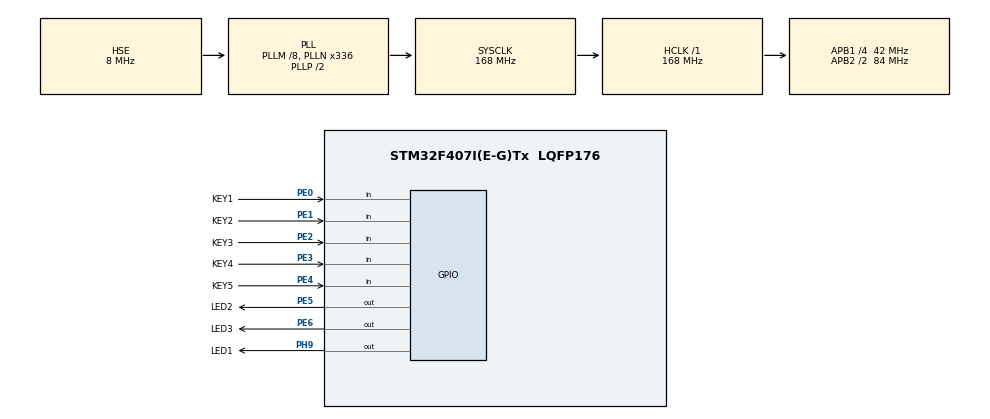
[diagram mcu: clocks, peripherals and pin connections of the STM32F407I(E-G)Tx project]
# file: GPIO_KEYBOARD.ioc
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Mcu.Family=STM32F4
PE0.GPIO_PuPd=GPIO_PULLUP
RCC.PLLSourceVirtual=RCC_PLLSOURCE_HSE
PH0-OSC_IN.Signal=RCC_OSC_IN
RCC.CortexFreq_Value=168000000
PE1.GPIO_PuPd=GPIO_PULLUP
PH9.GPIO_Speed=GPIO_SPEED_FREQ_VERY_HIGH
RCC.APB1CLKDivider=RCC_HCLK_DIV4
PE6.GPIO_Label=LED3
RCC.SYSCLKSource=RCC_SYSCLKSOURCE_PLLCLK
ProjectManager.StackSize=0x400
PA13.Signal=SYS_JTMS-SWDIO
ProjectManager.TargetToolchain=MDK-ARM V5.27
PH9.Signal=GPIO_Output
RCC.HCLKFreq_Value=168000000
RCC.APB2TimFreq_Value=168000000
PE5.Signal=GPIO_Output
PE1.Signal=GPIO_Input
RCC.LSE_VALUE=32768
RCC.AHBFreq_Value=168000000
PH0-OSC_IN.Mode=HSE-External-Oscillator
PE2.GPIO_PuPd=GPIO_PULLUP
RCC.HSE_VALUE=8000000
PH9.GPIO_Label=LED1
board=custom
RCC.VCOOutputFreq_Value=336000000
PE1.GPIO_Label=KEY2
RCC.APB2Freq_Value=84000000
PA14.Mode=Serial_Wire
PE4.GPIO_Label=KEY5
PE3.GPIO_PuPd=GPIO_PULLUP
PH1-OSC_OUT.Signal=RCC_OSC_OUT
PE2.Signal=GPIO_Input
PE6.Signal=GPIO_Output
PA13.Mode=Serial_Wire
PE4.Signal=GPIO_Input
Mcu.Name=STM32F407I(E-G)Tx
PE0.Signal=GPIO_Input
PE4.GPIO_PuPd=GPIO_PULLUP
PH1-OSC_OUT.Mode=HSE-External-Oscillator
RCC.48MHZClocksFreq_Value=84000000
RCC.SYSCLKFreq_VALUE=168000000
Mcu.Package=LQFP176
PE5.GPIO_Label=LED2
PA14.Signal=SYS_JTCK-SWCLK
ProjectManager.HeapSize=0x200
PE0.GPIO_Label=KEY1
RCC.HSI_VALUE=16000000
NVIC.PriorityGroup=NVIC_PRIORITYGROUP_4
RCC.APB2CLKDivider=RCC_HCLK_DIV2
RCC.PLLM=8
RCC.PLLN=336
PE5.GPIO_Speed=GPIO_SPEED_FREQ_VERY_HIGH
RCC.APB1TimFreq_Value=84000000
PE3.Signal=GPIO_Input
PE3.GPIO_Label=KEY4
RCC.APB1Freq_Value=42000000
PE6.GPIO_Speed=GPIO_SPEED_FREQ_VERY_HIGH
PE2.GPIO_Label=KEY3

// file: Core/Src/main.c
/* USER CODE BEGIN Header */
/**
  ******************************************************************************
  * @file           : main.c
  * @brief          : Main program body
  ******************************************************************************
  * @attention
  *
  * <h2><center>&copy; Copyright (c) 2020 STMicroelectronics.
  * All rights reserved.</center></h2>
  *
  * This software component is licensed by ST under BSD 3-Clause license,
  * the "License"; You may not use this file except in compliance with the
  * License. You may obtain a copy of the License at:
  *                        opensource.org/licenses/BSD-3-Clause
  *
  ******************************************************************************
  */
/* USER CODE END Header */
#include "main.h"
#include "gpio.h"

void SystemClock_Config(void);

int main(void)
{

  /* MCU Configuration--------------------------------------------------------*/

  /* Reset of all peripherals, Initializes the Flash interface and the Systick. */
  HAL_Init();

  /* Configure the system clock */
  SystemClock_Config();

  /* Initialize all configured peripherals */
  MX_GPIO_Init();

  /* Infinite loop */
  while (1)
  {

    /* USER CODE BEGIN 3 */
    if(HAL_GPIO_ReadPin(GPIOE,GPIO_PIN_0) == GPIO_PIN_RESET)
    {
      HAL_Delay(10);
      if(HAL_GPIO_ReadPin(GPIOE,GPIO_PIN_0) == GPIO_PIN_RESET)
      {
        while (HAL_GPIO_ReadPin(GPIOE,GPIO_PIN_0) != GPIO_PIN_SET);
        HAL_GPIO_WritePin(GPIOE,GPIO_PIN_5,GPIO_PIN_SET);
      }
    }
    else if(HAL_GPIO_ReadPin(GPIOE,GPIO_PIN_1) == GPIO_PIN_RESET)
    {
      HAL_Delay(10);
      if(HAL_GPIO_ReadPin(GPIOE,GPIO_PIN_1) == GPIO_PIN_RESET)
        {
          while (HAL_GPIO_ReadPin(GPIOE,GPIO_PIN_1) != GPIO_PIN_SET);
          HAL_GPIO_TogglePin(GPIOE,GPIO_PIN_6);
        }
    }

  }
  /* USER CODE END 3 */
}

void SystemClock_Config(void)
{
  RCC_OscInitTypeDef RCC_OscInitStruct = {0};
  RCC_ClkInitTypeDef RCC_ClkInitStruct = {0};

  /** Configure the main internal regulator output voltage
  */
  __HAL_RCC_PWR_CLK_ENABLE();
  __HAL_PWR_VOLTAGESCALING_CONFIG(PWR_REGULATOR_VOLTAGE_SCALE1);
  /** Initializes the RCC Oscillators according to the specified parameters
  * in the RCC_OscInitTypeDef structure.
  */
  RCC_OscInitStruct.OscillatorType = RCC_OSCILLATORTYPE_HSE;
  RCC_OscInitStruct.HSEState = RCC_HSE_ON;
  RCC_OscInitStruct.PLL.PLLState = RCC_PLL_ON;
  RCC_OscInitStruct.PLL.PLLSource = RCC_PLLSOURCE_HSE;
  RCC_OscInitStruct.PLL.PLLM = 8;
  RCC_OscInitStruct.PLL.PLLN = 336;
  RCC_OscInitStruct.PLL.PLLP = RCC_PLLP_DIV2;
  RCC_OscInitStruct.PLL.PLLQ = 4;
  if (HAL_RCC_OscConfig(&RCC_OscInitStruct) != HAL_OK)
  {
    Error_Handler();
  }
  /** Initializes the CPU, AHB and APB buses clocks
  */
  RCC_ClkInitStruct.ClockType = RCC_CLOCKTYPE_HCLK|RCC_CLOCKTYPE_SYSCLK
                              |RCC_CLOCKTYPE_PCLK1|RCC_CLOCKTYPE_PCLK2;
  RCC_ClkInitStruct.SYSCLKSource = RCC_SYSCLKSOURCE_PLLCLK;
  RCC_ClkInitStruct.AHBCLKDivider = RCC_SYSCLK_DIV1;
  RCC_ClkInitStruct.APB1CLKDivider = RCC_HCLK_DIV4;
  RCC_ClkInitStruct.APB2CLKDivider = RCC_HCLK_DIV2;

  if (HAL_RCC_ClockConfig(&RCC_ClkInitStruct, FLASH_LATENCY_5) != HAL_OK)
  {
    Error_Handler();
  }
}

void Error_Handler(void)
{
}

/************************ (C) COPYRIGHT STMicroelectronics *****END OF FILE****/
